# STM32F031K6U7 register map
File version: 1.0
Registers are 32-bit, access not given, reset 0x0 unless marked. A register's access mark holds for its fields unless they carry their own. Offsets are from the block's base; [hi:lo] are bit positions; {n}, {i} and the like mark numbered series; 'fields as' and 'values as' point back to an identical list.

## USART1
Base 0x40013800
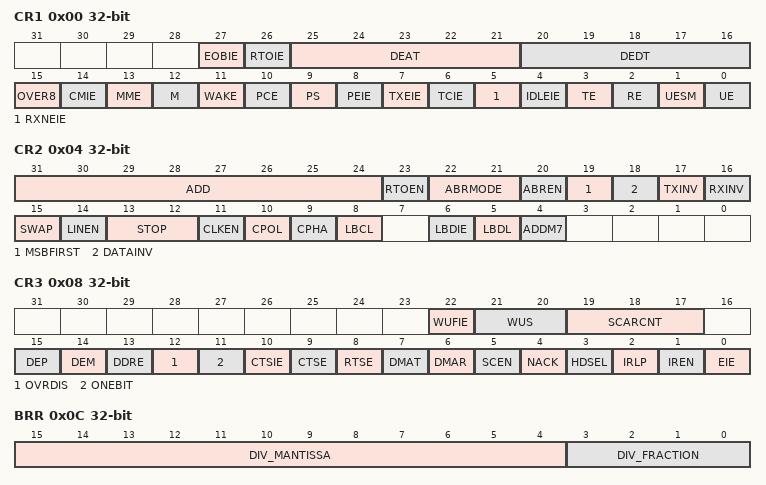
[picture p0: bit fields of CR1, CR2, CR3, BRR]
0x00 CR1
  [27] EOBIE, [26] RTOIE, [25:21] DEAT, [20:16] DEDT, [15] OVER8, [14] CMIE, [13] MME, [12] M, [11] WAKE, [10] PCE, [9] PS, [8] PEIE, [7] TXEIE, [6] TCIE, [5] RXNEIE, [4] IDLEIE, [3] TE, [2] RE, [1] UESM, [0] UE
0x04 CR2
  [31:24] ADD, [23] RTOEN, [22:21] ABRMODE, [20] ABREN, [19] MSBFIRST, [18] DATAINV, [17] TXINV, [16] RXINV, [15] SWAP, [14] LINEN, [13:12] STOP, [11] CLKEN, [10] CPOL, [9] CPHA, [8] LBCL, [6] LBDIE, [5] LBDL, [4] ADDM7
0x08 CR3
  [22] WUFIE, [21:20] WUS, [19:17] SCARCNT, [15] DEP, [14] DEM, [13] DDRE, [12] OVRDIS, [11] ONEBIT, [10] CTSIE, [9] CTSE, [8] RTSE, [7] DMAT, [6] DMAR, [5] SCEN, [4] NACK, [3] HDSEL, [2] IRLP, [1] IREN, [0] EIE
0x0C BRR
  [15:4] DIV_MANTISSA, [3:0] DIV_FRACTION
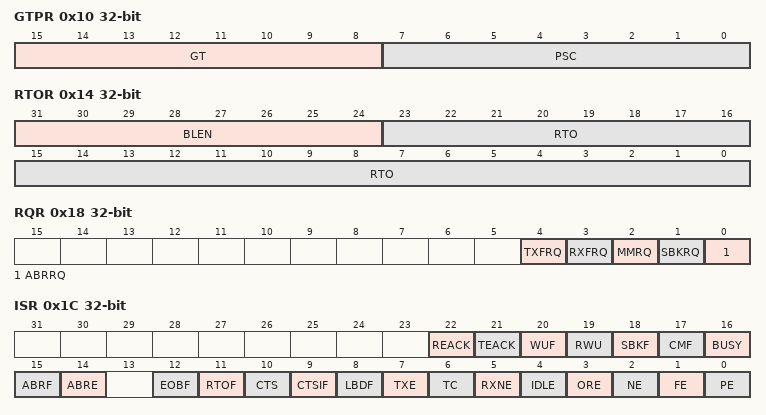
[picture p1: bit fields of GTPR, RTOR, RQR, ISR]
0x10 GTPR
  [15:8] GT, [7:0] PSC
0x14 RTOR
  [31:24] BLEN, [23:0] RTO
0x18 RQR
  [4] TXFRQ, [3] RXFRQ, [2] MMRQ, [1] SBKRQ, [0] ABRRQ
0x1C ISR
  [22] REACK, [21] TEACK, [20] WUF, [19] RWU, [18] SBKF, [17] CMF, [16] BUSY, [15] ABRF, [14] ABRE, [12] EOBF, [11] RTOF, [10] CTS, [9] CTSIF, [8] LBDF, [7] TXE, [6] TC, [5] RXNE, [4] IDLE, [3] ORE, [2] NE, [1] FE, [0] PE
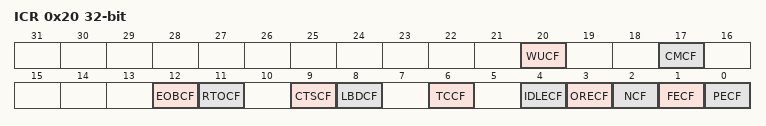
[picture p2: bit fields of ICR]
0x20 ICR
  [20] WUCF, [17] CMCF, [12] EOBCF, [11] RTOCF, [9] CTSCF, [8] LBDCF, [6] TCCF, [4] IDLECF, [3] ORECF, [2] NCF, [1] FECF, [0] PECF
0x24 RDR 16-bit
0x28 TDR 16-bit

## DBGMCU
Base 0x40015800
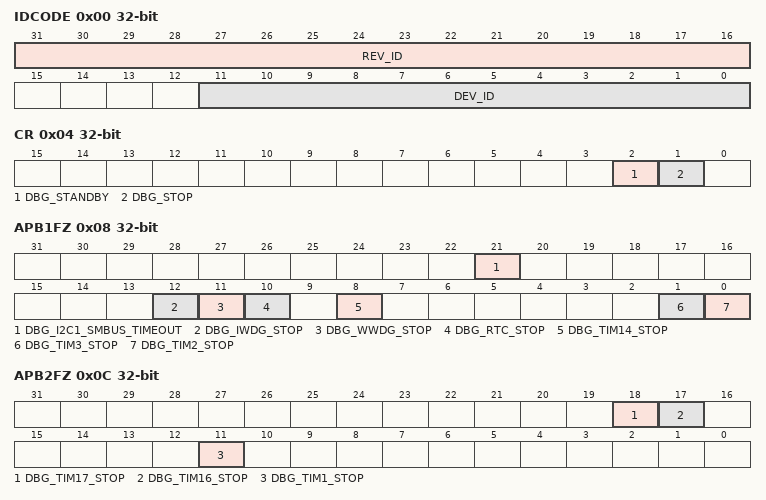
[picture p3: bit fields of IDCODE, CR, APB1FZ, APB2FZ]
0x00 IDCODE
  [31:16] REV_ID, [11:0] DEV_ID
0x04 CR
  [2] DBG_STANDBY, [1] DBG_STOP
0x08 APB1FZ
  [21] DBG_I2C1_SMBUS_TIMEOUT, [12] DBG_IWDG_STOP, [11] DBG_WWDG_STOP, [10] DBG_RTC_STOP, [8] DBG_TIM14_STOP, [1] DBG_TIM3_STOP, [0] DBG_TIM2_STOP
0x0C APB2FZ
  [18] DBG_TIM17_STOP, [17] DBG_TIM16_STOP, [11] DBG_TIM1_STOP

## DMA1
Base 0x40020000
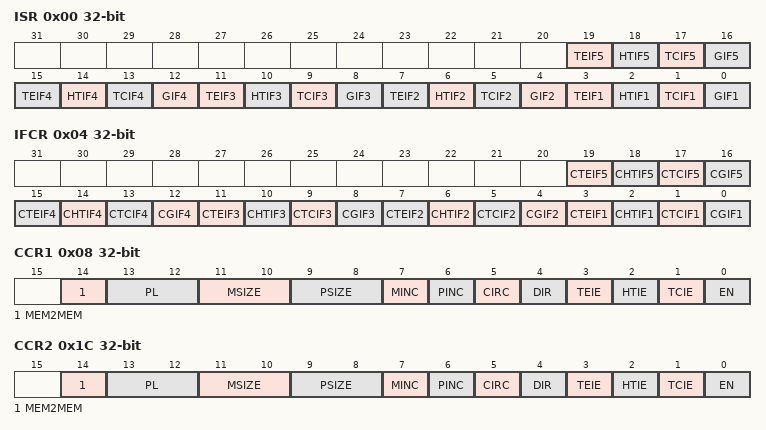
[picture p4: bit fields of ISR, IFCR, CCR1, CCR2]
0x00 ISR
  [4n-1] TEIF{n} (n=1..5), [4n-2] HTIF{n} (n=1..5), [4n-3] TCIF{n} (n=1..5), [4n-4] GIF{n} (n=1..5)
0x04 IFCR
  [4n-1] CTEIF{n} (n=1..5), [4n-2] CHTIF{n} (n=1..5), [4n-3] CTCIF{n} (n=1..5), [4n-4] CGIF{n} (n=1..5)
0x08 CCR1
  [14] MEM2MEM, [13:12] PL, [11:10] MSIZE, [9:8] PSIZE, [7] MINC, [6] PINC, [5] CIRC, [4] DIR, [3] TEIE, [2] HTIE, [1] TCIE, [0] EN
0x0C CNDTR1
  [15:0] NDT
0x10 CPAR1
  [31:0] PA
{0x0+0x14*i} CMAR{i} (i=1..5)
  [31:0] MA
0x1C CCR2
  fields as CCR1
0x20 CNDTR2
  [15:0] NDT
0x24 CPAR2
  [31:0] PA
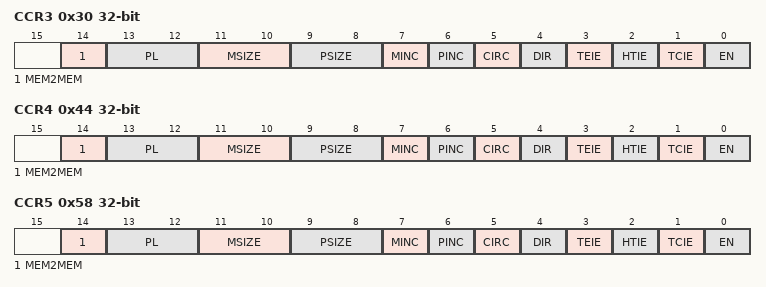
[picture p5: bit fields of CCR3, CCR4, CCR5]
0x30 CCR3
  fields as CCR1
0x34 CNDTR3
  [15:0] NDT
0x38 CPAR3
  [31:0] PA
0x44 CCR4
  fields as CCR1
0x48 CNDTR4
  [15:0] NDT
0x4C CPAR4
  [31:0] PA
0x58 CCR5
  fields as CCR1
0x5C CNDTR5
  [15:0] NDT
0x60 CPAR5
  [31:0] PA

## RCC
Base 0x40021000
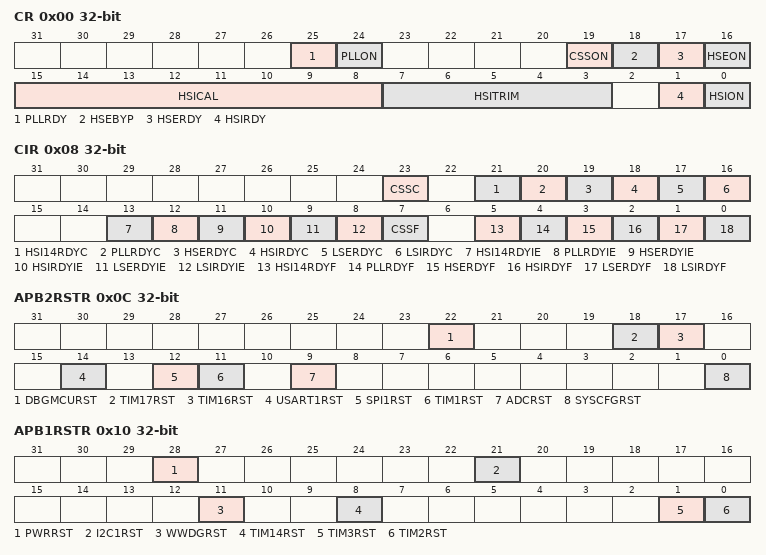
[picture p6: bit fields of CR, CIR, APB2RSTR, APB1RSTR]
0x00 CR
  [25] PLLRDY, [24] PLLON, [19] CSSON, [18] HSEBYP, [17] HSERDY, [16] HSEON, [15:8] HSICAL, [7:3] HSITRIM, [1] HSIRDY, [0] HSION
0x04 CFGR
  [31] PLLNODIV, [30:28] MCOPRE, [27:24] MCO, [21:18] PLLMUL, [17] PLLXTPRE, [16] PLLSRC, [14] ADCPRE, [10] PPRE_DIV2, [10:9] PPRE_DIV8, [10:8] PPRE_DIV4, [7:4] HPRE, [3:2] SWS, [1:0] SW
0x08 CIR
  [23] CSSC, [21] HSI14RDYC, [20] PLLRDYC, [19] HSERDYC, [18] HSIRDYC, [17] LSERDYC, [16] LSIRDYC, [13] HSI14RDYIE, [12] PLLRDYIE, [11] HSERDYIE, [10] HSIRDYIE, [9] LSERDYIE, [8] LSIRDYIE, [7] CSSF, [5] HSI14RDYF, [4] PLLRDYF, [3] HSERDYF, [2] HSIRDYF, [1] LSERDYF, [0] LSIRDYF
0x0C APB2RSTR
  [22] DBGMCURST, [18] TIM17RST, [17] TIM16RST, [14] USART1RST, [12] SPI1RST, [11] TIM1RST, [9] ADCRST, [0] SYSCFGRST
0x10 APB1RSTR
  [28] PWRRST, [21] I2C1RST, [11] WWDGRST, [8] TIM14RST, [1] TIM3RST, [0] TIM2RST
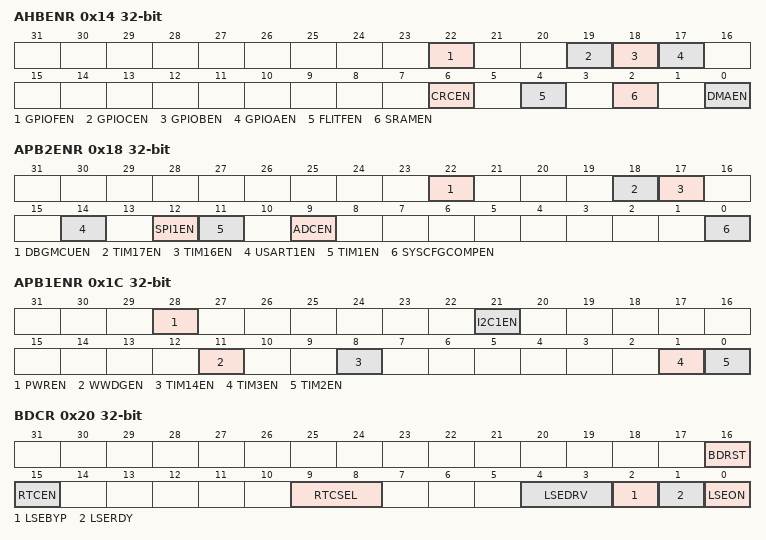
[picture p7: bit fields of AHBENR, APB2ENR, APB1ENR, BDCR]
0x14 AHBENR
  [22] GPIOFEN, [19] GPIOCEN, [18] GPIOBEN, [17] GPIOAEN, [6] CRCEN, [4] FLITFEN, [2] SRAMEN, [0] DMAEN
0x18 APB2ENR
  [22] DBGMCUEN, [18] TIM17EN, [17] TIM16EN, [14] USART1EN, [12] SPI1EN, [11] TIM1EN, [9] ADCEN, [0] SYSCFGCOMPEN
0x1C APB1ENR
  [28] PWREN, [21] I2C1EN, [11] WWDGEN, [8] TIM14EN, [1] TIM3EN, [0] TIM2EN
0x20 BDCR
  [16] BDRST, [15] RTCEN, [9:8] RTCSEL, [4:3] LSEDRV, [2] LSEBYP, [1] LSERDY, [0] LSEON
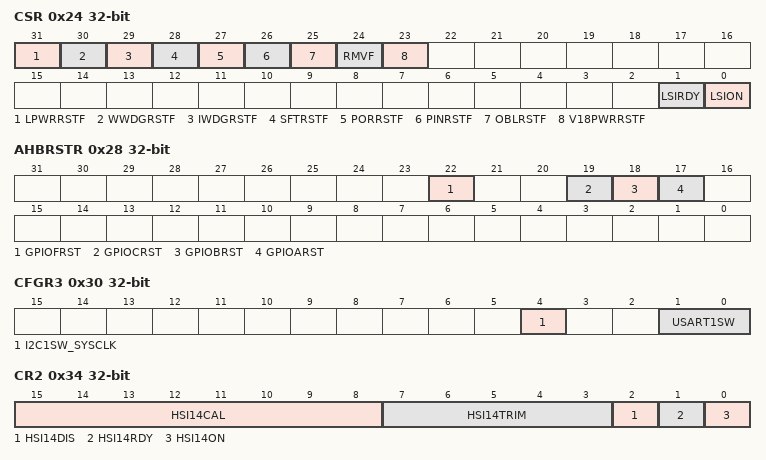
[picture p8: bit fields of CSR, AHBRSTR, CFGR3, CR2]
0x24 CSR
  [31] LPWRRSTF, [30] WWDGRSTF, [29] IWDGRSTF, [28] SFTRSTF, [27] PORRSTF, [26] PINRSTF, [25] OBLRSTF, [24] RMVF, [23] V18PWRRSTF, [1] LSIRDY, [0] LSION
0x28 AHBRSTR
  [22] GPIOFRST, [19] GPIOCRST, [18] GPIOBRST, [17] GPIOARST
0x2C CFGR2
  [3:0] PREDIV
0x30 CFGR3
  [4] I2C1SW_SYSCLK, [1:0] USART1SW
0x34 CR2
  [15:8] HSI14CAL, [7:3] HSI14TRIM, [2] HSI14DIS, [1] HSI14RDY, [0] HSI14ON

## FLASH
Base 0x40022000
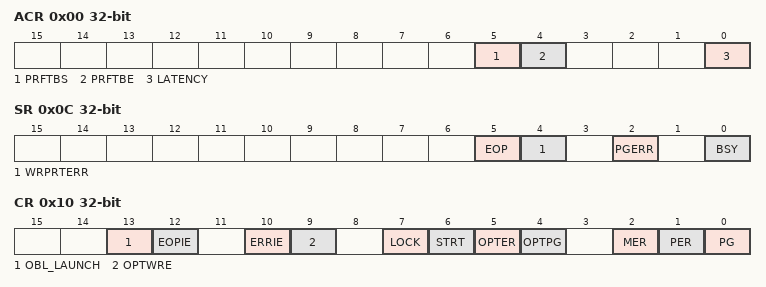
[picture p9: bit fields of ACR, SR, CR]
0x00 ACR
  [5] PRFTBS, [4] PRFTBE, [0] LATENCY
0x04 KEYR
  [31:0] FKEYR
0x08 OPTKEYR
0x0C SR
  [5] EOP, [4] WRPRTERR, [2] PGERR, [0] BSY
0x10 CR
  [13] OBL_LAUNCH, [12] EOPIE, [10] ERRIE, [9] OPTWRE, [7] LOCK, [6] STRT, [5] OPTER, [4] OPTPG, [2] MER, [1] PER, [0] PG
0x14 AR
  [31:0] FAR
0x1C OBR
  [31:24] DATA1, [23:16] DATA0, [14] RAM_PARITY_CHECK, [13] VDDA_MONITOR, [12] nBOOT1, [10] nRST_STDBY, [9] nRST_STOP, [14:8] USER, [2] RDPRT2, [1] RDPRT1, [0] OPTERR
0x20 WRPR
  [15:0] WRP

## CRC
Base 0x40023000
0x00 DR
0x04 IDR 8-bit
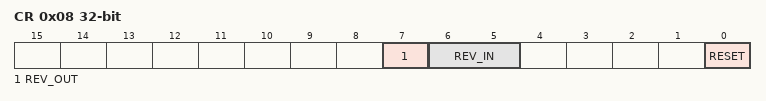
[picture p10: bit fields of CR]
0x08 CR
  [7] REV_OUT, [6:5] REV_IN, [0] RESET
0x10 INIT

## GPIOA
Base 0x48000000
Same registers: GPIOB 0x48000400, GPIOC 0x48000800, GPIOF 0x48001400
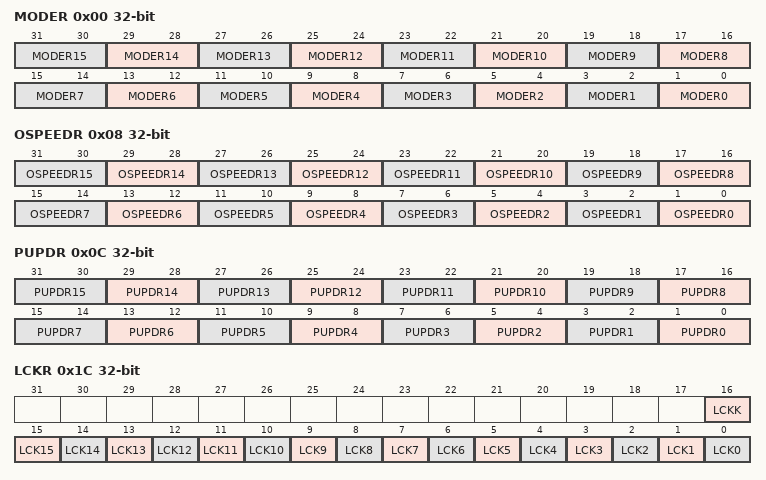
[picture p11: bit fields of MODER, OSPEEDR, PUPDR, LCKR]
0x00 MODER
  [2n+1:2n] MODER{n} (n=0..15)
0x04 OTYPER
0x08 OSPEEDR
  [2n+1:2n] OSPEEDR{n} (n=0..15)
0x0C PUPDR
  [2n+1:2n] PUPDR{n} (n=0..15)
0x10 IDR
0x14 ODR
0x18 BSRR
0x1C LCKR
  [16] LCKK, [n] LCK{n} (n=0..15)
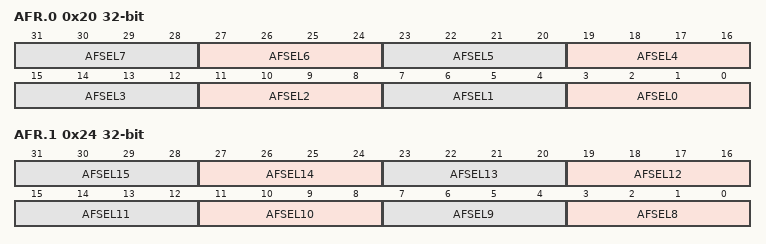
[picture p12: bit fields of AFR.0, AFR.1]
0x20 AFR.0
  [4n+3:4n] AFSEL{n} (n=0..7)
0x24 AFR.1
  [4n-29:4n-32] AFSEL{n} (n=8..15)
0x28 BRR
